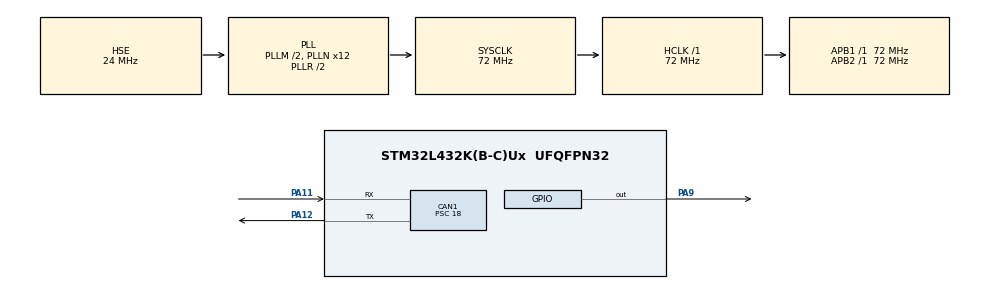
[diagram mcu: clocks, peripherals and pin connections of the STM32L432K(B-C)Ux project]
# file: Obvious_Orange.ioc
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CAN1.BS1=CAN_BS1_5TQ
CAN1.BS2=CAN_BS2_2TQ
CAN1.CalculateBaudRate=500000
CAN1.CalculateTimeBit=2000
CAN1.CalculateTimeQuantum=250.0
CAN1.Prescaler=18
Mcu.Family=STM32L4
Mcu.Name=STM32L432K(B-C)Ux
Mcu.Package=UFQFPN32
NVIC.CAN1_RX0_IRQn=true\:0\:0\:false\:false\:true\:true\:true\:true
NVIC.CAN1_RX1_IRQn=true\:0\:0\:false\:false\:true\:true\:true\:true
NVIC.PriorityGroup=NVIC_PRIORITYGROUP_4
PA0.Mode=HSE-External-Clock-Source-for-LittleOrca
PA0.Signal=RCC_CK_IN
PA11.Mode=CAN_Activate
PA11.Signal=CAN1_RX
PA12.Mode=CAN_Activate
PA12.Signal=CAN1_TX
PA13\ (JTMS-SWDIO).Mode=Serial_Wire
PA13\ (JTMS-SWDIO).Signal=SYS_JTMS-SWDIO
PA14\ (JTCK-SWCLK).Mode=Serial_Wire
PA14\ (JTCK-SWCLK).Signal=SYS_JTCK-SWCLK
PA9.Signal=GPIO_Output
ProjectManager.HeapSize=0x200
ProjectManager.StackSize=0x400
ProjectManager.TargetToolchain=STM32CubeIDE
RCC.ADCFreq_Value=48000000
RCC.AHBFreq_Value=72000000
RCC.APB1Freq_Value=72000000
RCC.APB1TimFreq_Value=72000000
RCC.APB2Freq_Value=72000000
RCC.APB2TimFreq_Value=72000000
RCC.CortexFreq_Value=72000000
RCC.HCLKFreq_Value=72000000
RCC.HSE_VALUE=24000000
RCC.HSI48_VALUE=48000000
RCC.HSI_VALUE=16000000
RCC.LSE_VALUE=32768
RCC.MSI_VALUE=4000000
RCC.PLLM=2
RCC.PLLN=12
RCC.PLLSourceVirtual=RCC_PLLSOURCE_HSE
RCC.SYSCLKFreq_VALUE=72000000
RCC.SYSCLKSource=RCC_SYSCLKSOURCE_PLLCLK
RCC.USBFreq_Value=48000000
RCC.VCOOutputFreq_Value=144000000
board=custom

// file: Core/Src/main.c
/* USER CODE BEGIN Header */
/**
  ******************************************************************************
  * @file           : main.c
  * @brief          : Main program body
  ******************************************************************************
  * @attention
  *
  * <h2><center>&copy; Copyright (c) 2021 STMicroelectronics.
  * All rights reserved.</center></h2>
  *
  * This software component is licensed by ST under BSD 3-Clause license,
  * the "License"; You may not use this file except in compliance with the
  * License. You may obtain a copy of the License at:
  *                        opensource.org/licenses/BSD-3-Clause
  *
  ******************************************************************************
  */
/* USER CODE END Header */
#include "main.h"

 CAN_HandleTypeDef hcan1;

void SystemClock_Config(void);
static void MX_GPIO_Init(void);
static void MX_CAN1_Init(void);

/* USER CODE BEGIN 0 */

CAN_TxHeaderTypeDef TxHeader;
CAN_RxHeaderTypeDef RxHeader;

uint8_t TxData[8];
uint8_t RxData[8];

uint32_t TxMailbox;

int datacheck = 0;

void HAL_CAN_RxFifo1MsgPendingCallback(CAN_HandleTypeDef *hcan)
{
	HAL_CAN_GetRxMessage(hcan, CAN_RX_FIFO1, &RxHeader, RxData);
	if (RxHeader.DLC == 2)
	{
		datacheck = 1;
	}
}

/* USER CODE END 0 */

int main(void)
{

  /* MCU Configuration--------------------------------------------------------*/

  /* Reset of all peripherals, Initializes the Flash interface and the Systick. */
  HAL_Init();

  /* Configure the system clock */
  SystemClock_Config();

  /* Initialize all configured peripherals */
  MX_GPIO_Init();
  MX_CAN1_Init();
  /* USER CODE BEGIN 2 */

  HAL_CAN_Start(&hcan1);

  // Activate the notification
  HAL_CAN_ActivateNotification(&hcan1, CAN_IT_RX_FIFO1_MSG_PENDING);

  TxHeader.DLC = 2;  // data length
  TxHeader.IDE = CAN_ID_STD;
  TxHeader.RTR = CAN_RTR_DATA;
  TxHeader.StdId = 0x103;  // ID
  TxHeader.TransmitGlobalTime = DISABLE;

  TxData[0] = 200;  // ms delay
  TxData[1] = 20;  // loop rep

  /* USER CODE END 2 */

  /* Infinite loop */
  while (1)
  {

    /* USER CODE BEGIN 3 */

	  HAL_Delay (1000);

	  if (datacheck)
	  {
		  // blink the LED
		  for (int i=0; i<RxData[1]; i++)
		  {
			  HAL_GPIO_TogglePin(GPIOA, GPIO_PIN_9);
			  HAL_Delay(RxData[0]);
		  }

		  datacheck = 0;

		  HAL_CAN_AddTxMessage(&hcan1, &TxHeader, TxData, &TxMailbox);

	  }
  }
  /* USER CODE END 3 */
}

void SystemClock_Config(void)
{
  RCC_OscInitTypeDef RCC_OscInitStruct = {0};
  RCC_ClkInitTypeDef RCC_ClkInitStruct = {0};

  /** Configure the main internal regulator output voltage
  */
  if (HAL_PWREx_ControlVoltageScaling(PWR_REGULATOR_VOLTAGE_SCALE1) != HAL_OK)
  {
    Error_Handler();
  }

  /** Initializes the RCC Oscillators according to the specified parameters
  * in the RCC_OscInitTypeDef structure.
  */
  RCC_OscInitStruct.OscillatorType = RCC_OSCILLATORTYPE_HSE;
  RCC_OscInitStruct.HSEState = RCC_HSE_BYPASS;
  RCC_OscInitStruct.PLL.PLLState = RCC_PLL_ON;
  RCC_OscInitStruct.PLL.PLLSource = RCC_PLLSOURCE_HSE;
  RCC_OscInitStruct.PLL.PLLM = 2;
  RCC_OscInitStruct.PLL.PLLN = 12;
  RCC_OscInitStruct.PLL.PLLP = RCC_PLLP_DIV7;
  RCC_OscInitStruct.PLL.PLLQ = RCC_PLLQ_DIV2;
  RCC_OscInitStruct.PLL.PLLR = RCC_PLLR_DIV2;
  if (HAL_RCC_OscConfig(&RCC_OscInitStruct) != HAL_OK)
  {
    Error_Handler();
  }

  /** Initializes the CPU, AHB and APB buses clocks
  */
  RCC_ClkInitStruct.ClockType = RCC_CLOCKTYPE_HCLK|RCC_CLOCKTYPE_SYSCLK
                              |RCC_CLOCKTYPE_PCLK1|RCC_CLOCKTYPE_PCLK2;
  RCC_ClkInitStruct.SYSCLKSource = RCC_SYSCLKSOURCE_PLLCLK;
  RCC_ClkInitStruct.AHBCLKDivider = RCC_SYSCLK_DIV1;
  RCC_ClkInitStruct.APB1CLKDivider = RCC_HCLK_DIV1;
  RCC_ClkInitStruct.APB2CLKDivider = RCC_HCLK_DIV1;

  if (HAL_RCC_ClockConfig(&RCC_ClkInitStruct, FLASH_LATENCY_4) != HAL_OK)
  {
    Error_Handler();
  }
}

static void MX_CAN1_Init(void)
{

  hcan1.Instance = CAN1;
  hcan1.Init.Prescaler = 18;
  hcan1.Init.Mode = CAN_MODE_NORMAL;
  hcan1.Init.SyncJumpWidth = CAN_SJW_1TQ;
  hcan1.Init.TimeSeg1 = CAN_BS1_5TQ;
  hcan1.Init.TimeSeg2 = CAN_BS2_2TQ;
  hcan1.Init.TimeTriggeredMode = DISABLE;
  hcan1.Init.AutoBusOff = DISABLE;
  hcan1.Init.AutoWakeUp = DISABLE;
  hcan1.Init.AutoRetransmission = DISABLE;
  hcan1.Init.ReceiveFifoLocked = DISABLE;
  hcan1.Init.TransmitFifoPriority = DISABLE;
  if (HAL_CAN_Init(&hcan1) != HAL_OK)
  {
    Error_Handler();
  }
  /* USER CODE BEGIN CAN1_Init 2 */

  CAN_FilterTypeDef canfilterconfig;

  canfilterconfig.FilterActivation = CAN_FILTER_ENABLE;
  canfilterconfig.FilterBank = 0;  // which filter bank to use from the assigned ones
  canfilterconfig.FilterFIFOAssignment = CAN_FILTER_FIFO1;
  canfilterconfig.FilterIdHigh = 0;
  canfilterconfig.FilterIdLow = 0;
  canfilterconfig.FilterMaskIdHigh = 0;
  canfilterconfig.FilterMaskIdLow = 0x0000;
  canfilterconfig.FilterMode = CAN_FILTERMODE_IDMASK;
  canfilterconfig.FilterScale = CAN_FILTERSCALE_32BIT;
  canfilterconfig.SlaveStartFilterBank = 14;  // how many filters to assign to the CAN1 (master can)

  HAL_CAN_ConfigFilter(&hcan1, &canfilterconfig);

  /* USER CODE END CAN1_Init 2 */

}

static void MX_GPIO_Init(void)
{
  GPIO_InitTypeDef GPIO_InitStruct = {0};

  /* GPIO Ports Clock Enable */
  __HAL_RCC_GPIOA_CLK_ENABLE();

  /*Configure GPIO pin Output Level */
  HAL_GPIO_WritePin(GPIOA, GPIO_PIN_9, GPIO_PIN_RESET);

  /*Configure GPIO pin : PA9 */
  GPIO_InitStruct.Pin = GPIO_PIN_9;
  GPIO_InitStruct.Mode = GPIO_MODE_OUTPUT_PP;
  GPIO_InitStruct.Pull = GPIO_NOPULL;
  GPIO_InitStruct.Speed = GPIO_SPEED_FREQ_LOW;
  HAL_GPIO_Init(GPIOA, &GPIO_InitStruct);

}

void Error_Handler(void)
{
  __disable_irq();
  while (1)
  {
  }
}
